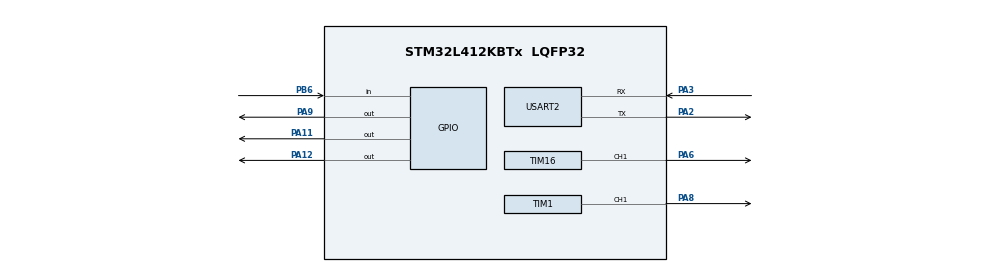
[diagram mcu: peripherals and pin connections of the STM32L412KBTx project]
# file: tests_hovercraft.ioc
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Mcu.Family=STM32L4
Mcu.Name=STM32L412KBTx
Mcu.Package=LQFP32
NVIC.PriorityGroup=NVIC_PRIORITYGROUP_4
PA11.Signal=GPIO_Output
PA12.Signal=GPIO_Output
PA2.Mode=Asynchronous
PA2.Signal=USART2_TX
PA3.Mode=Asynchronous
PA3.Signal=USART2_RX
PA6.Signal=S_TIM16_CH1
PA8.Signal=S_TIM1_CH1
PA9.Signal=GPIO_Output
PB6.Signal=GPIO_Input
ProjectManager.HeapSize=0x200
ProjectManager.StackSize=0x400
ProjectManager.TargetToolchain=STM32CubeIDE
RCC.ADCFreq_Value=4000000
RCC.HSE_VALUE=8000000
RCC.HSI48_VALUE=48000000
RCC.HSI_VALUE=16000000
RCC.LSE_VALUE=32768
RCC.MSI_VALUE=4000000
RCC.USBFreq_Value=4000000
RCC.VCOOutputFreq_Value=32000000
SH.S_TIM16_CH1.0=TIM16_CH1,PWM Generation1 CH1
SH.S_TIM1_CH1.0=TIM1_CH1,PWM Generation1 CH1
TIM1.Channel-PWM\ Generation1\ CH1=TIM_CHANNEL_1
TIM16.Channel=TIM_CHANNEL_1
USART2.VirtualMode-Asynchronous=VM_ASYNC
VP_TIM16_VS_ClockSourceINT.Mode=Enable_Timer
VP_TIM1_VS_ClockSourceINT.Mode=Internal
board=custom

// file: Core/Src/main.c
/* USER CODE BEGIN Header */
/**
  ******************************************************************************
  * @file           : main.c
  * @brief          : Main program body
  ******************************************************************************
  * @attention
  *
  * Copyright (c) 2023 STMicroelectronics.
  * All rights reserved.
  *
  * This software is licensed under terms that can be found in the LICENSE file
  * in the root directory of this software component.
  * If no LICENSE file comes with this software, it is provided AS-IS.
  *
  ******************************************************************************
  */
/* USER CODE END Header */
#include "main.h"

TIM_HandleTypeDef htim1;
TIM_HandleTypeDef htim16;

UART_HandleTypeDef huart2;

void SystemClock_Config(void);
static void MX_GPIO_Init(void);
static void MX_TIM1_Init(void);
static void MX_TIM16_Init(void);
static void MX_USART2_UART_Init(void);

int main(void)
{

  /* MCU Configuration--------------------------------------------------------*/

  /* Reset of all peripherals, Initializes the Flash interface and the Systick. */
  HAL_Init();

  /* Configure the system clock */
  SystemClock_Config();

  /* Initialize all configured peripherals */
  MX_GPIO_Init();
  MX_TIM1_Init();
  MX_TIM16_Init();
  MX_USART2_UART_Init();
  /* USER CODE BEGIN 2 */
  HAL_TIM_PWM_Start(&htim1, TIM_CHANNEL_1);
  HAL_TIM_PWM_Start(&htim16, TIM_CHANNEL_1);

  testmoteur();

  /* USER CODE END 2 */

  /* Infinite loop */
  while (1)
  {

  }
}

void SystemClock_Config(void)
{
  RCC_OscInitTypeDef RCC_OscInitStruct = {0};
  RCC_ClkInitTypeDef RCC_ClkInitStruct = {0};

  /** Configure the main internal regulator output voltage
  */
  if (HAL_PWREx_ControlVoltageScaling(PWR_REGULATOR_VOLTAGE_SCALE1) != HAL_OK)
  {
    Error_Handler();
  }

  /** Initializes the RCC Oscillators according to the specified parameters
  * in the RCC_OscInitTypeDef structure.
  */
  RCC_OscInitStruct.OscillatorType = RCC_OSCILLATORTYPE_MSI;
  RCC_OscInitStruct.MSIState = RCC_MSI_ON;
  RCC_OscInitStruct.MSICalibrationValue = 0;
  RCC_OscInitStruct.MSIClockRange = RCC_MSIRANGE_6;
  RCC_OscInitStruct.PLL.PLLState = RCC_PLL_NONE;
  if (HAL_RCC_OscConfig(&RCC_OscInitStruct) != HAL_OK)
  {
    Error_Handler();
  }

  /** Initializes the CPU, AHB and APB buses clocks
  */
  RCC_ClkInitStruct.ClockType = RCC_CLOCKTYPE_HCLK|RCC_CLOCKTYPE_SYSCLK
                              |RCC_CLOCKTYPE_PCLK1|RCC_CLOCKTYPE_PCLK2;
  RCC_ClkInitStruct.SYSCLKSource = RCC_SYSCLKSOURCE_MSI;
  RCC_ClkInitStruct.AHBCLKDivider = RCC_SYSCLK_DIV1;
  RCC_ClkInitStruct.APB1CLKDivider = RCC_HCLK_DIV1;
  RCC_ClkInitStruct.APB2CLKDivider = RCC_HCLK_DIV1;

  if (HAL_RCC_ClockConfig(&RCC_ClkInitStruct, FLASH_LATENCY_0) != HAL_OK)
  {
    Error_Handler();
  }
}

static void MX_TIM1_Init(void)
{

  TIM_ClockConfigTypeDef sClockSourceConfig = {0};
  TIM_MasterConfigTypeDef sMasterConfig = {0};
  TIM_OC_InitTypeDef sConfigOC = {0};
  TIM_BreakDeadTimeConfigTypeDef sBreakDeadTimeConfig = {0};

  htim1.Instance = TIM1;
  htim1.Init.Prescaler = 0;
  htim1.Init.CounterMode = TIM_COUNTERMODE_UP;
  htim1.Init.Period = 65535;
  htim1.Init.ClockDivision = TIM_CLOCKDIVISION_DIV1;
  htim1.Init.RepetitionCounter = 0;
  htim1.Init.AutoReloadPreload = TIM_AUTORELOAD_PRELOAD_DISABLE;
  if (HAL_TIM_Base_Init(&htim1) != HAL_OK)
  {
    Error_Handler();
  }
  sClockSourceConfig.ClockSource = TIM_CLOCKSOURCE_INTERNAL;
  if (HAL_TIM_ConfigClockSource(&htim1, &sClockSourceConfig) != HAL_OK)
  {
    Error_Handler();
  }
  if (HAL_TIM_PWM_Init(&htim1) != HAL_OK)
  {
    Error_Handler();
  }
  sMasterConfig.MasterOutputTrigger = TIM_TRGO_RESET;
  sMasterConfig.MasterOutputTrigger2 = TIM_TRGO2_RESET;
  sMasterConfig.MasterSlaveMode = TIM_MASTERSLAVEMODE_DISABLE;
  if (HAL_TIMEx_MasterConfigSynchronization(&htim1, &sMasterConfig) != HAL_OK)
  {
    Error_Handler();
  }
  sConfigOC.OCMode = TIM_OCMODE_PWM1;
  sConfigOC.Pulse = 0;
  sConfigOC.OCPolarity = TIM_OCPOLARITY_HIGH;
  sConfigOC.OCNPolarity = TIM_OCNPOLARITY_HIGH;
  sConfigOC.OCFastMode = TIM_OCFAST_DISABLE;
  sConfigOC.OCIdleState = TIM_OCIDLESTATE_RESET;
  sConfigOC.OCNIdleState = TIM_OCNIDLESTATE_RESET;
  if (HAL_TIM_PWM_ConfigChannel(&htim1, &sConfigOC, TIM_CHANNEL_1) != HAL_OK)
  {
    Error_Handler();
  }
  sBreakDeadTimeConfig.OffStateRunMode = TIM_OSSR_DISABLE;
  sBreakDeadTimeConfig.OffStateIDLEMode = TIM_OSSI_DISABLE;
  sBreakDeadTimeConfig.LockLevel = TIM_LOCKLEVEL_OFF;
  sBreakDeadTimeConfig.DeadTime = 0;
  sBreakDeadTimeConfig.BreakState = TIM_BREAK_DISABLE;
  sBreakDeadTimeConfig.BreakPolarity = TIM_BREAKPOLARITY_HIGH;
  sBreakDeadTimeConfig.BreakFilter = 0;
  sBreakDeadTimeConfig.Break2State = TIM_BREAK2_DISABLE;
  sBreakDeadTimeConfig.Break2Polarity = TIM_BREAK2POLARITY_HIGH;
  sBreakDeadTimeConfig.Break2Filter = 0;
  sBreakDeadTimeConfig.AutomaticOutput = TIM_AUTOMATICOUTPUT_DISABLE;
  if (HAL_TIMEx_ConfigBreakDeadTime(&htim1, &sBreakDeadTimeConfig) != HAL_OK)
  {
    Error_Handler();
  }
  HAL_TIM_MspPostInit(&htim1);

}

static void MX_TIM16_Init(void)
{

  TIM_OC_InitTypeDef sConfigOC = {0};
  TIM_BreakDeadTimeConfigTypeDef sBreakDeadTimeConfig = {0};

  htim16.Instance = TIM16;
  htim16.Init.Prescaler = 0;
  htim16.Init.CounterMode = TIM_COUNTERMODE_UP;
  htim16.Init.Period = 65535;
  htim16.Init.ClockDivision = TIM_CLOCKDIVISION_DIV1;
  htim16.Init.RepetitionCounter = 0;
  htim16.Init.AutoReloadPreload = TIM_AUTORELOAD_PRELOAD_DISABLE;
  if (HAL_TIM_Base_Init(&htim16) != HAL_OK)
  {
    Error_Handler();
  }
  if (HAL_TIM_PWM_Init(&htim16) != HAL_OK)
  {
    Error_Handler();
  }
  sConfigOC.OCMode = TIM_OCMODE_PWM1;
  sConfigOC.Pulse = 0;
  sConfigOC.OCPolarity = TIM_OCPOLARITY_HIGH;
  sConfigOC.OCNPolarity = TIM_OCNPOLARITY_HIGH;
  sConfigOC.OCFastMode = TIM_OCFAST_DISABLE;
  sConfigOC.OCIdleState = TIM_OCIDLESTATE_RESET;
  sConfigOC.OCNIdleState = TIM_OCNIDLESTATE_RESET;
  if (HAL_TIM_PWM_ConfigChannel(&htim16, &sConfigOC, TIM_CHANNEL_1) != HAL_OK)
  {
    Error_Handler();
  }
  sBreakDeadTimeConfig.OffStateRunMode = TIM_OSSR_DISABLE;
  sBreakDeadTimeConfig.OffStateIDLEMode = TIM_OSSI_DISABLE;
  sBreakDeadTimeConfig.LockLevel = TIM_LOCKLEVEL_OFF;
  sBreakDeadTimeConfig.DeadTime = 0;
  sBreakDeadTimeConfig.BreakState = TIM_BREAK_DISABLE;
  sBreakDeadTimeConfig.BreakPolarity = TIM_BREAKPOLARITY_HIGH;
  sBreakDeadTimeConfig.AutomaticOutput = TIM_AUTOMATICOUTPUT_DISABLE;
  if (HAL_TIMEx_ConfigBreakDeadTime(&htim16, &sBreakDeadTimeConfig) != HAL_OK)
  {
    Error_Handler();
  }
  HAL_TIM_MspPostInit(&htim16);

}

static void MX_USART2_UART_Init(void)
{

  huart2.Instance = USART2;
  huart2.Init.BaudRate = 115200;
  huart2.Init.WordLength = UART_WORDLENGTH_8B;
  huart2.Init.StopBits = UART_STOPBITS_1;
  huart2.Init.Parity = UART_PARITY_NONE;
  huart2.Init.Mode = UART_MODE_TX_RX;
  huart2.Init.HwFlowCtl = UART_HWCONTROL_NONE;
  huart2.Init.OverSampling = UART_OVERSAMPLING_16;
  huart2.Init.OneBitSampling = UART_ONE_BIT_SAMPLE_DISABLE;
  huart2.AdvancedInit.AdvFeatureInit = UART_ADVFEATURE_NO_INIT;
  if (HAL_UART_Init(&huart2) != HAL_OK)
  {
    Error_Handler();
  }

}

static void MX_GPIO_Init(void)
{
  GPIO_InitTypeDef GPIO_InitStruct = {0};

  /* GPIO Ports Clock Enable */
  __HAL_RCC_GPIOA_CLK_ENABLE();
  __HAL_RCC_GPIOB_CLK_ENABLE();

  /*Configure GPIO pin Output Level */
  HAL_GPIO_WritePin(GPIOA, GPIO_PIN_9|GPIO_PIN_11|GPIO_PIN_12, GPIO_PIN_RESET);

  /*Configure GPIO pins : PA9 PA11 PA12 */
  GPIO_InitStruct.Pin = GPIO_PIN_9|GPIO_PIN_11|GPIO_PIN_12;
  GPIO_InitStruct.Mode = GPIO_MODE_OUTPUT_PP;
  GPIO_InitStruct.Pull = GPIO_NOPULL;
  GPIO_InitStruct.Speed = GPIO_SPEED_FREQ_LOW;
  HAL_GPIO_Init(GPIOA, &GPIO_InitStruct);

  /*Configure GPIO pin : PB6 */
  GPIO_InitStruct.Pin = GPIO_PIN_6;
  GPIO_InitStruct.Mode = GPIO_MODE_INPUT;
  GPIO_InitStruct.Pull = GPIO_NOPULL;
  HAL_GPIO_Init(GPIOB, &GPIO_InitStruct);

}

/* USER CODE BEGIN 4 */
void testmoteur(void)
{	/*1 itération 0.1s?*/
	/*total 10s?*/
	for(int i=0;i<100;i++){
		__HAL_TIM_SET_COMPARE(&htim2, TIM_CHANNEL_1, 250);
		HAL_Delay(50);
		__HAL_TIM_SET_COMPARE(&htim2, TIM_CHANNEL_1, 500);
		HAL_Delay(50);
	}
}
/* USER CODE END 4 */

void Error_Handler(void)
{
  __disable_irq();
  while (1)
  {
  }
}
